# apollo3p register map
Vendor: Ambiq Micro; Series: Apollo; File version: 1.0
CPU: CM4 r1p0, little endian, MPU, FPU, I-cache, D-cache, VTOR, ITCM, DTCM, 3 interrupt priority bits, 0 interrupts
Registers are 32-bit, read-write, reset 0x0 unless marked. A register's access mark holds for its fields unless they carry their own. Offsets are from the block's base; [hi:lo] are bit positions; 'fields as' and 'values as' point back to an identical list.

## APBDMA — APB DMA Register Interfaces
Base 0x40011000
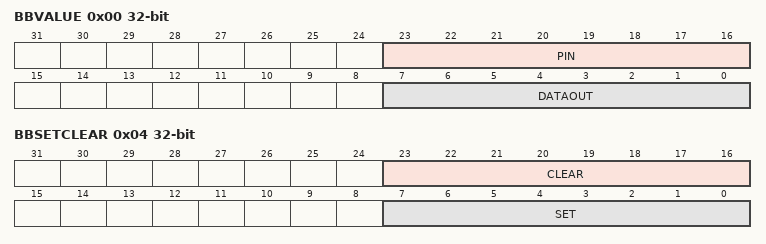
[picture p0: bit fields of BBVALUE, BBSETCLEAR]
0x00 BBVALUE — Control Register
  [23:16] PIN — PIO values
  [7:0] DATAOUT — Data Output Values
0x04 BBSETCLEAR — Set/Clear Register
  [23:16] CLEAR — Write 1 to clear PIO value
  [7:0] SET — Write 1 to set PIO value (set higher priority then clear if both bits are set)
0x08 BBINPUT — PIO Input Values
  [7:0] DATAIN — PIO values
0x20 DEBUGDATA — PIO Input Values
0x40 DEBUG — PIO Input Values
  [3:0] DEBUGEN — Debug Enable
    0=OFF (Debug Disabled); 1=ARB (Debug ARB values)

## RSTGEN — MCU Reset Generator
Base 0x40000000
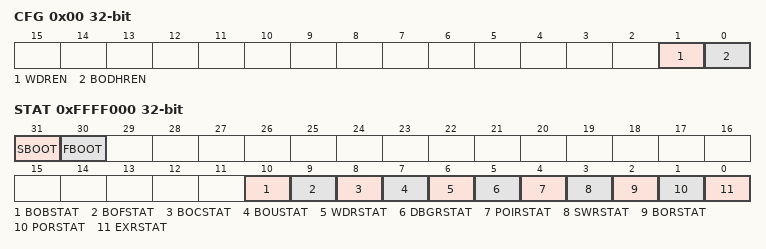
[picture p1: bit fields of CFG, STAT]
0x00 CFG — Reset configuration register. This controls the reset enables for brownout condition, and for the expiration of the watch dog timer.
  [1] WDREN — Watchdog Timer Reset Enable. NOTE: The WDT module must also be configured for WDT reset. This includes enabling the RESEN bit in WDTCFG register in Watch dog timer block.
  [0] BODHREN — Brown out high (2.1 V) reset enable.
0x04 SWPOI — This is the software POI reset. writing the key value to this register will trigger a POI to the system. This will cause a reset to all blocks except for registers in clock gen, RTC and the STIMER.
  [7:0] SWPOIKEY — 0x1B generates a software POI reset. This is a write-only register. Reading from this register will yield only all 0's.
    27=KEYVALUE (Writing 0x1B key value generates a software POI reset.)
0x08 SWPOR — This is the software POR reset. Writing the key value to this register will trigger a POR to the system. This will cause a reset to all blocks except for registers in clock gen, RTC, power management unit, the STIMER, and the power management unit.
  [7:0] SWPORKEY — 0xD4 generates a software POR reset.
    212=KEYVALUE (Writing 0xD4 key value generates a software POR reset.)
0x14 TPIURST — This will trigger a reset for the TPIU unit.
  [0] TPIURST — Static reset for the TPIU. Write to '1' to assert reset to TPIU. Write to '0' to clear the reset.
0x200 INTEN — Set bits in this register to allow this module to generate the corresponding interrupt.
  [0] BODH — Enables an interrupt that triggers when VCC is below BODH level.
0x204 INTSTAT — Read bits from this register to discover the cause of a recent interrupt.
  fields as INTEN
0x208 INTCLR — Write a 1 to a bit in this register to clear the interrupt status associated with that bit.
  fields as INTEN
0x20C INTSET — Write a 1 to a bit in this register to instantly generate an interrupt from this module. (Generally used for testing purposes).
  fields as INTEN
0xFFFF000 STAT — This register contains the status for brownout events and the causes for resets. NOTE 1: All bits in this register, including reserved bits, are writable. Therefore care should be taken not to write this register. NOTE 2: This register does not retain its value across a core deep sleep cycle. Therefore applications needing to use this value after deep sleep must copy and save this register to SRAM before initiating the first deep sleep cycle.
  [31] SBOOT — Set when booting securely (SBL).
  [30] FBOOT — Set if current boot was initiated by soft reset and resulted in Fast Boot (SBL).
  [10] BOBSTAT — A BLE/Burst Regulator Brownout Event occurred (SBL).
  [9] BOFSTAT — A Memory Regulator Brownout Event occurred (SBL).
  [8] BOCSTAT — A Core Regulator Brownout Event occurred (SBL).
  [7] BOUSTAT — An Unregulated Supply Brownout Event occurred (SBL).
  [6] WDRSTAT — Reset was initiated by a Watchdog Timer Reset (SBL).
  [5] DBGRSTAT — Reset was a initiated by Debugger Reset (SBL).
  [4] POIRSTAT — Reset was a initiated by Software POI Reset (SBL).
  [3] SWRSTAT — Reset was a initiated by SW POR or AIRCR Reset (SBL).
  [2] BORSTAT — Reset was initiated by a Brown-Out Reset (SBL).
  [1] PORSTAT — Reset was initiated by a Power-On Reset (SBL).
  [0] EXRSTAT — Reset was initiated by an External Reset (SBL).
